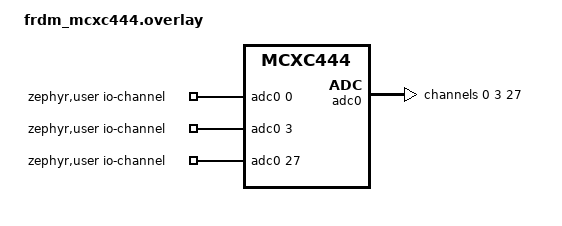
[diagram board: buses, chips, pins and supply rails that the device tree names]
/*
 * SPDX-License-Identifier: Apache-2.0
 *
 * Copyright 2024, 2026 NXP
 */

/ {
	zephyr,user {
		io-channels = <&adc0 0>, <&adc0 3>, <&adc0 27>;
	};
};

&adc0 {
	#address-cells = <1>;
	#size-cells = <0>;
	bandgap-supply = <&bandgap_buffer>;

	channel@0 {
		reg = <0>;
		zephyr,gain = "ADC_GAIN_1";
		zephyr,reference = "ADC_REF_VDD_1";
		zephyr,vref-mv = <3300>;
		zephyr,acquisition-time = <ADC_ACQ_TIME_DEFAULT>;
		zephyr,resolution = <12>;
	};

	channel@3 {
		reg = <3>;
		zephyr,gain = "ADC_GAIN_1";
		zephyr,reference = "ADC_REF_VDD_1";
		zephyr,vref-mv = <3300>;
		zephyr,acquisition-time = <ADC_ACQ_TIME_DEFAULT>;
		zephyr,resolution = <12>;
	};

	/* Internal bandgap, buffered by the PMC. */
	channel@1b {
		reg = <27>;
		zephyr,gain = "ADC_GAIN_1";
		zephyr,reference = "ADC_REF_VDD_1";
		zephyr,vref-mv = <3300>;
		zephyr,acquisition-time = <ADC_ACQ_TIME_DEFAULT>;
		zephyr,resolution = <12>;
	};
};
